# GD32H71x_72x register map
File version: 1.0
CPU: CM7 r1p2, little endian, MPU, FPU, 4 interrupt priority bits
Registers are 32-bit, read-write, reset 0x0 unless marked. A register's access mark holds for its fields unless they carry their own. Offsets are from the block's base; [hi:lo] are bit positions.

## TIMER5 — Basic-timers
Base 0x40001000
Same registers: TIMER6 0x40001400
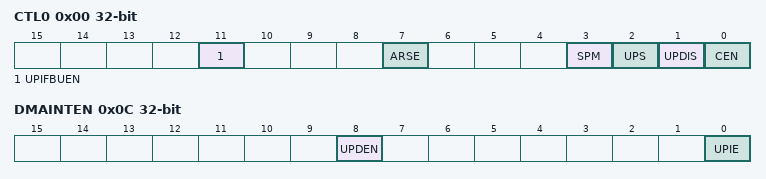
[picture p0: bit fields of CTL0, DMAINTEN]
0x00 CTL0 — control register 0
  [11] UPIFBUEN — UPIF bit backup enable
  [7] ARSE — Auto-reload preload enable
  [3] SPM — One-pulse mode
  [2] UPS — Update request source
  [1] UPDIS — Update disable
  [0] CEN — Counter enable
0x04 CTL1 — control register 1
  [6:4] MMC0 — Master mode selection
0x0C DMAINTEN — DMA/Interrupt enable register
  [8] UPDEN — Update DMA request enable
  [0] UPIE — Update interrupt enable
0x10 INTF0 — status register
  [0] UPIF — Update interrupt flag
0x14 SWEVG wo — event generation register
  [0] UPG — Update generation
0x24 CNT — counter
  [31:0] CNT — Low counter value
0x28 PSC — prescaler
  [15:0] PSC — Prescaler value
0x2C CARL — Counter auto-reload low register
  [31:0] CARL — Low Auto-reload value

## TIMER50 — Basic-timers
Base 0x4000F000
Same registers: TIMER51 0x4000F400
Registers as TIMER5, without INTF0, CNT; these are added or differ:
0x10 INTF — status register
  [0] UPIF — Update interrupt flag
0x24 CNTL — counter
  [31:0] CNTL — Low counter value
0x2C CARL — Counter auto-reload low register
  [31:0] CARLL — Low Auto-reload value
0xD0 CNTH — Counter high register
  [31:0] CNTH32_63
0xD4 CARH — Counter auto reload high register
  [31:0] CARLH32_63

## TMU — Trigonometric math unit
Base 0x48024400
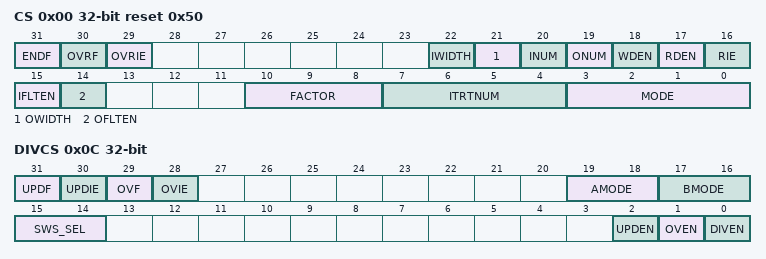
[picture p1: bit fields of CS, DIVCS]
0x00 CS access per field reset 0x50 — Control and status register
  [31] ENDF ro — End of TMU operation flag
  [30] OVRF rw — The flag of overflow
  [29] OVRIE rw — Overflow interrupt enable
  [22] IWIDTH rw — Width of input data
  [21] OWIDTH rw — Width of output data
  [20] INUM rw — The number of times that the TMU_IDATA needs to be written
  [19] ONUM rw — The number of times that the TMU_ODATA needs to be read
  [18] WDEN rw — Enable DMA request to write TMU_IDATA
  [17] RDEN rw — Enable DMA request to read TMU_ODATA
  [16] RIE rw — Enable interrupt request to read TMU_ODATA
  [15] IFLTEN rw — Input floating point format enable
  [14] OFLTEN rw — Output floating point format enable
  [10:8] FACTOR rw — Scaling factor
  [7:4] ITRTNUM rw — Number of iterations
  [3:0] MODE rw — Mode of TMU operation
0x04 IDATA wo — Input data register
  [31:0] IDATA — The input data
0x08 ODATA ro — Output data register
  [31:0] ODATA — The output data
0x0C DIVCS — Divider control and status register
  [31] UPDF — Divider result update flag
  [30] UPDIE — Divider result update flag interrupt enable
  [29] OVF — Divider result overflow (divided by 0) flag
  [28] OVIE — Divider result overflow (divided by 0) interrupt enable
  [19:18] AMODE — Dividend data mode.
  [17:16] BMODE — Divisor data mode.
  [15:14] SWS_SEL — Divider operation software start selection.
  [2] UPDEN — Divider result update enable.
  [1] OVEN — Divider result overflow(divided by 0) detect function enable.
  [0] DIVEN — Divider module enable
0x10 DIVD_HDATA — Dividend high data register
  [31:0] DIVD_HDATA — This field stores the high 32 bits [63:32] of the 64-bit dividend value for division operation.
0x14 DIVD_LDATA — Dividend low data register
  [31:0] DIVD_LDATA — This field stores the low 32 bits [31:0] of the 64-bit dividend value for division operation.
0x18 DIVS_HDATA — Divisor high data register
  [31:0] DIVS_HDATA — This field stores the high 32 bits [63:32] of the 64-bit divisor value for division operation.
0x1C DIVS_LDATA — Divisor low data register
  [31:0] DIVS_LDATA — This field stores the low 32 bits [31:0] of the 64-bit divisor value for division operation.
0x20 QUO_HDATA ro — Quotient high data register
  [31:0] QUO_HDATA — This field contains the high-order 32 bits [95:64] of the division result quotient.
0x24 QUO_MDATA ro — Quotient middle data register
  [31:0] QUO_MDATA — This field contains the middle-order 32 bits [63:32] of the division result quotient.
0x28 QUO_LDATA ro — Quotient low data register
  [31:0] QUO_LDATA — This field contains the low-order 32 bits [63:32] of the division result quotient.
0x2C REM_HDATA ro — Remainder high data register
  [31:0] REM_HDATA — This field contains the upper 32 bits [95:64] of the 96-bit remainder result from division operation.
0x30 REM_MDATA ro — Remainder middle data register
  [31:0] REM_MDATA — This field contains the middle 32 bits [63:32] of the 96-bit remainder result from division operation.
0x34 REM_LDATA ro — Remainder low data register
  [31:0] REM_LDATA — This field contains the low 32 bits [31:0] of the 96-bit remainder result from division operation.
